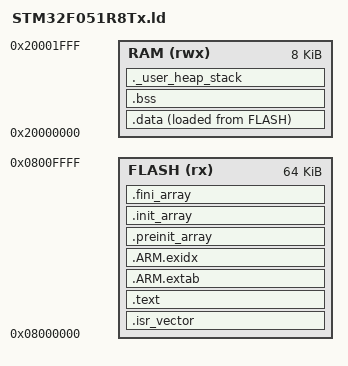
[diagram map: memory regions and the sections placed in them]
/* STM32F051R8: 64 КБ flash, 8 КБ RAM */
ENTRY(Reset_Handler)

MEMORY
{
    FLASH (rx)  : ORIGIN = 0x08000000, LENGTH = 64K
    RAM   (rwx) : ORIGIN = 0x20000000, LENGTH = 8K
}

_estack = ORIGIN(RAM) + LENGTH(RAM);
_min_stack_size = 0xC00; /* 3 КБ: разбор SMS + лог с vsnprintf внутри — около 1.5 КБ, берём с запасом */
_min_heap_size  = 0;

SECTIONS
{
    .isr_vector : { KEEP(*(.isr_vector)) } > FLASH

    .text :
    {
        *(.text*)
        *(.rodata*)
        KEEP(*(.init))
        KEEP(*(.fini))
        . = ALIGN(4);
    } > FLASH

    .ARM.extab : { *(.ARM.extab* .gnu.linkonce.armextab.*) } > FLASH
    .ARM.exidx :
    {
        __exidx_start = .;
        *(.ARM.exidx* .gnu.linkonce.armexidx.*)
        __exidx_end = .;
    } > FLASH

    .preinit_array :
    {
        PROVIDE_HIDDEN(__preinit_array_start = .);
        KEEP(*(.preinit_array*))
        PROVIDE_HIDDEN(__preinit_array_end = .);
    } > FLASH
    .init_array :
    {
        PROVIDE_HIDDEN(__init_array_start = .);
        KEEP(*(SORT(.init_array.*)))
        KEEP(*(.init_array*))
        PROVIDE_HIDDEN(__init_array_end = .);
    } > FLASH
    .fini_array :
    {
        PROVIDE_HIDDEN(__fini_array_start = .);
        KEEP(*(SORT(.fini_array.*)))
        KEEP(*(.fini_array*))
        PROVIDE_HIDDEN(__fini_array_end = .);
    } > FLASH

    _sidata = LOADADDR(.data);

    .data :
    {
        . = ALIGN(4);
        _sdata = .;
        *(.data*)
        . = ALIGN(4);
        _edata = .;
    } > RAM AT > FLASH

    .bss (NOLOAD) :
    {
        . = ALIGN(4);
        _sbss = .;
        *(.bss*)
        *(COMMON)
        . = ALIGN(4);
        _ebss = .;
    } > RAM

    /* Только проверка, что стек помещается: линковка упадёт, если RAM не хватает. */
    ._user_heap_stack (NOLOAD) :
    {
        . = ALIGN(8);
        PROVIDE(end = .);
        PROVIDE(_end = .);
        . = . + _min_heap_size;
        . = . + _min_stack_size;
        . = ALIGN(8);
    } > RAM

}
